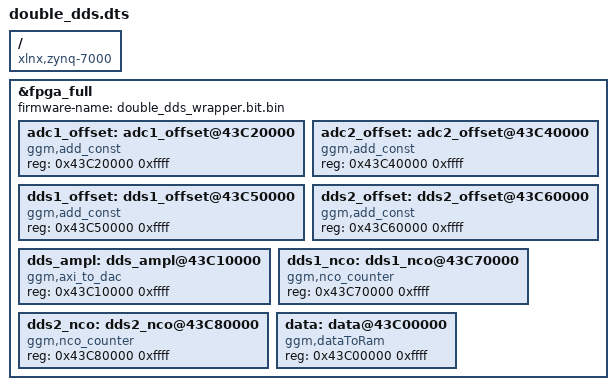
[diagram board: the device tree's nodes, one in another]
/dts-v1/;
/plugin/;

/ {
	compatible = "xlnx,zynq-7000";

	fragment0 {
		target = <&fpga_full>;
		#address-cells = <1>;
		#size-cells = <1>;
		__overlay__ {
			#address-cells = <1>;
			#size-cells = <1>;

			firmware-name = "double_dds_wrapper.bit.bin";

			adc1_offset: adc1_offset@43C20000{
				compatible = "ggm,add_const";
				reg = <0x43C20000 0xffff>;
			};

			adc2_offset: adc2_offset@43C40000{
				compatible = "ggm,add_const";
				reg = <0x43C40000 0xffff>;
			};

			dds1_offset: dds1_offset@43C50000{
				compatible = "ggm,add_const";
				reg = <0x43C50000 0xffff>;
			};

			dds2_offset: dds2_offset@43C60000{
				compatible = "ggm,add_const";
				reg = <0x43C60000 0xffff>;
			};

			dds_ampl: dds_ampl@43C10000{
				compatible = "ggm,axi_to_dac";
				reg = <0x43C10000 0xffff>;
			};

			dds1_nco: dds1_nco@43C70000{
				compatible = "ggm,nco_counter";
				reg = <0x43C70000 0xffff>;
			};

			dds2_nco: dds2_nco@43C80000{
				compatible = "ggm,nco_counter";
				reg = <0x43C80000 0xffff>;
			};

			data: data@43C00000{
				compatible = "ggm,dataToRam";
				reg = <0x43C00000 0xffff>;
			};

		};
	};
};
